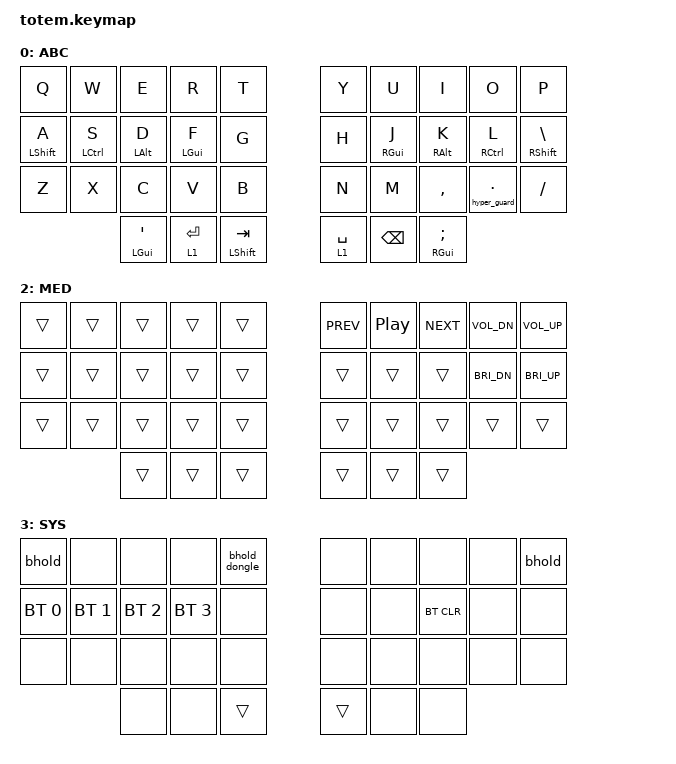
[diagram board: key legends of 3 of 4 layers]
#include <behaviors.dtsi>
#include <dt-bindings/zmk/keys.h>
#include <dt-bindings/zmk/bt.h>
#include <dt-bindings/zmk/outputs.h>

// Home row mods macro
#define HRML(k1,k2,k3,k4) &hml LSHFT k1 &hml LCTRL k2  &hml LALT k3  &hml LGUI k4
#define HRMR(k1,k2,k3,k4) &hmr RGUI k1  &hmr RALT k2  &hmr RCTRL k3  &hmr RSHFT k4

// Key positions for positional hold-tap, kept for reference. Currently unused:
// the homerow mods below deliberately do NOT use cross-hand gating (see the
// note on `hml`). This board is a TOTEMIST (36 keys), so these match the
// standard 36-key numbering -- see the matrix transform in
// config/boards/shields/totem/totem.dtsi:
//   Row 0:     0  1  2  3  4  |  5  6  7  8  9
//   Row 1:    10 11 12 13 14  | 15 16 17 18 19
//   Row 2:    20 21 22 23 24  | 25 26 27 28 29
//   Thumbs:      30 31 32     | 33 34 35
// The keymap mirrors the Toucan2's, minus its outer pinky columns and
// trackpad layer.
#define KEYS_L 0 1 2 3 4 10 11 12 13 14 20 21 22 23 24   // left-hand keys
#define KEYS_R 5 6 7 8 9 15 16 17 18 19 25 26 27 28 29   // right-hand keys
#define THUMBS 30 31 32 33 34 35                         // thumb keys

#define L0 0
#define L1 1
#define L2 2
#define L3 3

// Layer-tap, used by the left Enter/L1 and right Space/L1 thumbs.
//
// ZMK's stock `&lt` is `tap-preferred`, which only resolves a hold when the
// tapping term expires -- pressing and releasing another key while it is held
// does NOT trigger the hold. So a quick layer chord (hold the thumb, tap a
// key, release) completed inside 200ms emits SPACE plus that key instead of
// the layer keycode. `balanced` resolves the hold as soon as another key is
// pressed and released, which is exactly what a layer chord looks like.
&lt {
    flavor = "balanced";
    tapping-term-ms = <175>;
    quick-tap-ms = <125>;
};

/ {
    behaviors {
        // Thumb hold-tap: quote/Cmd on the left outer thumb and
        // semicolon/Cmd on the right outer thumb.
        //
        // Deliberately has NO `global-quick-tap` / `require-prior-idle-ms`.
        // Those make ZMK resolve the key to an *instant tap* whenever any other
        // key was pressed within the preceding window, no matter how long or
        // how hard the key is then held -- see is_quick_tap() in ZMK's
        // behavior_hold_tap.c. Since Shift is nearly always pressed immediately
        // after typing a letter, that reliably emitted TAB instead of SHIFT.
        //
        // Prior-idle gating is right for homerow mods (see hml/hmr below), but
        // wrong for thumbs, which are never pressed accidentally while typing.
        ht: hold_tap {
            label = "hold_tap";
            compatible = "zmk,behavior-hold-tap";
            #binding-cells = <2>;
            flavor = "balanced";
            tapping-term-ms = <175>;
            quick-tap-ms = <125>;
            bindings = <&kp>, <&kp>;
        };

        // Tab/Shift on the left inner thumb. `hold-preferred` makes Shift
        // win as soon as another key goes down, so a fast Shift+A roll that
        // lets go of the thumb before the letter still types `A`.
        shift_tab: shift_tab {
            compatible = "zmk,behavior-hold-tap";
            #binding-cells = <2>;
            flavor = "hold-preferred";
            tapping-term-ms = <175>;
            quick-tap-ms = <125>;
            bindings = <&kp>, <&kp>;
        };

        // These symbol combos keep their output unchanged while Shift is held.
        lpar_fixed: lpar_fixed {
            compatible = "zmk,behavior-mod-morph";
            #binding-cells = <0>;
            bindings = <&kp LPAR>, <&kp LPAR>;
            mods = <(MOD_LSFT|MOD_RSFT)>;
        };
        rpar_fixed: rpar_fixed {
            compatible = "zmk,behavior-mod-morph";
            #binding-cells = <0>;
            bindings = <&kp RPAR>, <&kp RPAR>;
            mods = <(MOD_LSFT|MOD_RSFT)>;
        };
        lbkt_fixed: lbkt_fixed {
            compatible = "zmk,behavior-mod-morph";
            #binding-cells = <0>;
            bindings = <&kp LBKT>, <&kp LBKT>;
            mods = <(MOD_LSFT|MOD_RSFT)>;
        };
        rbkt_fixed: rbkt_fixed {
            compatible = "zmk,behavior-mod-morph";
            #binding-cells = <0>;
            bindings = <&kp RBKT>, <&kp RBKT>;
            mods = <(MOD_LSFT|MOD_RSFT)>;
        };
        lbrc_fixed: lbrc_fixed {
            compatible = "zmk,behavior-mod-morph";
            #binding-cells = <0>;
            bindings = <&kp LBRC>, <&kp LBRC>;
            mods = <(MOD_LSFT|MOD_RSFT)>;
        };
        rbrc_fixed: rbrc_fixed {
            compatible = "zmk,behavior-mod-morph";
            #binding-cells = <0>;
            bindings = <&kp RBRC>, <&kp RBRC>;
            mods = <(MOD_LSFT|MOD_RSFT)>;
        };
        minus_fixed: minus_fixed {
            compatible = "zmk,behavior-mod-morph";
            #binding-cells = <0>;
            bindings = <&kp MINUS>, <&kp MINUS>;
            mods = <(MOD_LSFT|MOD_RSFT)>;
        };
        equal_fixed: equal_fixed {
            compatible = "zmk,behavior-mod-morph";
            #binding-cells = <0>;
            bindings = <&kp EQUAL>, <&kp EQUAL>;
            mods = <(MOD_LSFT|MOD_RSFT)>;
        };
        under_fixed: under_fixed {
            compatible = "zmk,behavior-mod-morph";
            #binding-cells = <0>;
            bindings = <&kp UNDER>, <&kp UNDER>;
            mods = <(MOD_LSFT|MOD_RSFT)>;
        };
        plus_fixed: plus_fixed {
            compatible = "zmk,behavior-mod-morph";
            #binding-cells = <0>;
            bindings = <&kp PLUS>, <&kp PLUS>;
            mods = <(MOD_LSFT|MOD_RSFT)>;
        };
        grave_fixed: grave_fixed {
            compatible = "zmk,behavior-mod-morph";
            #binding-cells = <0>;
            bindings = <&kp GRAVE>, <&kp GRAVE>;
            mods = <(MOD_LSFT|MOD_RSFT)>;
        };
        tilde_fixed: tilde_fixed {
            compatible = "zmk,behavior-mod-morph";
            #binding-cells = <0>;
            bindings = <&kp TILDE>, <&kp TILDE>;
            mods = <(MOD_LSFT|MOD_RSFT)>;
        };
        dqt_fixed: dqt_fixed {
            compatible = "zmk,behavior-mod-morph";
            #binding-cells = <0>;
            bindings = <&kp DQT>, <&kp DQT>;
            mods = <(MOD_LSFT|MOD_RSFT)>;
        };
        sqt_fixed: sqt_fixed {
            compatible = "zmk,behavior-mod-morph";
            #binding-cells = <0>;
            bindings = <&kp SQT>, <&kp SQT>;
            mods = <(MOD_LSFT|MOD_RSFT)>;
        };
        colon_fixed: colon_fixed {
            compatible = "zmk,behavior-mod-morph";
            #binding-cells = <0>;
            bindings = <&kp COLON>, <&kp COLON>;
            mods = <(MOD_LSFT|MOD_RSFT)>;
        };
        semi_fixed: semi_fixed {
            compatible = "zmk,behavior-mod-morph";
            #binding-cells = <0>;
            bindings = <&kp SEMI>, <&kp SEMI>;
            mods = <(MOD_LSFT|MOD_RSFT)>;
        };

        // Homerow mods.
        //
        // NOTE: no `hold-trigger-key-positions` / `hold-trigger-on-release`.
        // Those implement urob's cross-hand ("timeless") positional hold-tap,
        // where a homerow mod can ONLY resolve as a hold if the next key is on
        // the opposite half. That gate is absolute -- there is no timeout
        // escape hatch -- so holding LGUI (F) and pressing C, both left hand,
        // can never become a hold and just emits "fc". That breaks the whole
        // left-hand shortcut cluster (CMD/CTRL + Q W A S Z X C V) and every
        // left-hand capital via LSHFT on A.
        //
        // With the positional gate removed, `require-prior-idle-ms` is the
        // main guard against false mods mid-word, and the tapping term becomes
        // the window in which a same-hand roll could still resolve as a hold
        // (balanced resolves on the other key's release). 190ms with a 100ms
        // prior-idle (was 220/150) biases toward HOLD, since missed holds
        // proved far more common than false ones.
        //
        // Trade-off: a fast same-hand roll that *starts* on the homerow after
        // >100ms idle ("as", "sad", "fad") can register a mod. If that becomes
        // the more annoying failure mode, re-add the two properties below
        // (KEYS_R THUMBS for hml, KEYS_L THUMBS for hmr) and use combos for
        // same-hand shortcuts, which is how urob handles it.
        hml: home_row_mod_left {
            label = "hrm_left";
            compatible = "zmk,behavior-hold-tap";
            #binding-cells = <2>;
            flavor = "balanced";
            tapping-term-ms = <190>;
            quick-tap-ms = <120>;
            require-prior-idle-ms = <100>;
            bindings = <&kp>, <&kp>;
        };

        hmd: home_row_mod_d {
            label = "hrm_d";
            compatible = "zmk,behavior-hold-tap";
            #binding-cells = <2>;
            flavor = "balanced";
            tapping-term-ms = <160>;
            quick-tap-ms = <120>;
            require-prior-idle-ms = <50>;
            bindings = <&kp>, <&kp>;
        };

        hmr: home_row_mod_right {
            label = "hrm_right";
            compatible = "zmk,behavior-hold-tap";
            #binding-cells = <2>;
            flavor = "balanced";
            tapping-term-ms = <190>;
            quick-tap-ms = <120>;
            require-prior-idle-ms = <100>;
            bindings = <&kp>, <&kp>;
        };

        // Software bootloader entry for the maintenance layer. This uses a
        // dedicated long-press behavior instead of `zmk,behavior-hold-tap`.
        // Both inner thumbs are hold-tap keys, and ZMK v0.3 rejects a second
        // hold-tap while either thumb remains held. Tap does nothing; a 2s+
        // hold invokes `&bootloader` with the original key's split source.
        //
        // This exists because ZMK behaviors with BEHAVIOR_LOCALITY_EVENT_SOURCE
        // (which &bootloader uses) execute on whichever half the triggering
        // key physically lives on, even though all keymap/behavior logic runs
        // on the central (left) half -- so P, physically on the
        // right board, reliably bootloaders the right half over BLE even
        // when its physical reset button doesn't.
        bhold: bootloader_hold {
            label = "bootloader_hold";
            compatible = "zmk,behavior-long-press";
            #binding-cells = <0>;
            duration-ms = <2000>;
            bindings = <&bootloader>;
        };

        // Same 2s hold, retargeted at the split central via `central`. In
        // dongle mode that is the keyless dongle, which otherwise has no way
        // into its UF2 bootloader short of opening its case to reach the reset
        // button. Standalone, the central is the left half, so this simply
        // duplicates the left pinky hold.
        bhold_dongle: bootloader_hold_dongle {
            compatible = "zmk,behavior-long-press";
            #binding-cells = <0>;
            duration-ms = <2000>;
            bindings = <&bootloader>;
            central;
        };
        // `&kp` that drops the key while Ctrl, Shift, Alt and GUI are all
        // held. Resting on the four left homerow mods resolves them all as
        // holds, and with `.` that is macOS's sysdiagnose chord, which kept
        // firing by accident. Any other modifier combination is unaffected.
        hyper_guard: hyper_guard {
            compatible = "zmk,behavior-hyper-guard";
            #binding-cells = <1>;
        };
    };

    combos {
        compatible = "zmk,combos";
        // Letter combos need both keys within 21ms (ZMK's default is 50ms), so
        // quick rolls while typing, like O then P, stay as plain letters.
        combo_esc_op {
            timeout-ms = <21>;
            key-positions = <8 9>;  // Combo o+p for ESCAPE
            bindings = <&kp ESC>;
        };
        combo_esc_qw {
            timeout-ms = <21>;
            key-positions = <0 1>;  // Combo q+w for ESCAPE
            bindings = <&kp ESC>;
        };
        // Symbol combos work on every layer and ignore held Shift.
        combo_left_paren {
            timeout-ms = <21>;
            key-positions = <22 23>;  // C+V
            bindings = <&lpar_fixed>;
        };
        combo_right_paren {
            timeout-ms = <21>;
            key-positions = <26 27>;  // M+COMMA
            bindings = <&rpar_fixed>;
        };
        combo_left_bracket {
            timeout-ms = <21>;
            key-positions = <12 13>;  // D+F
            bindings = <&lbkt_fixed>;
        };
        combo_right_bracket {
            timeout-ms = <21>;
            key-positions = <16 17>;  // J+K
            bindings = <&rbkt_fixed>;
        };
        combo_left_brace {
            timeout-ms = <21>;
            key-positions = <2 3>;  // E+R
            bindings = <&lbrc_fixed>;
        };
        combo_right_brace {
            timeout-ms = <21>;
            key-positions = <6 7>;  // U+I
            bindings = <&rbrc_fixed>;
        };
        combo_minus {
            timeout-ms = <21>;
            key-positions = <21 22>;  // X+C
            bindings = <&minus_fixed>;
        };
        combo_equal {
            timeout-ms = <21>;
            key-positions = <27 28>;  // COMMA+.
            bindings = <&equal_fixed>;
        };
        combo_underscore {
            timeout-ms = <21>;
            key-positions = <1 2>;  // W+E
            bindings = <&under_fixed>;
        };
        combo_plus {
            timeout-ms = <21>;
            key-positions = <7 8>;  // I+O
            bindings = <&plus_fixed>;
        };
        combo_grave {
            timeout-ms = <21>;
            key-positions = <10 11>;  // A+S
            bindings = <&grave_fixed>;
        };
        combo_tilde {
            timeout-ms = <21>;
            key-positions = <18 19>;  // L+backslash
            bindings = <&tilde_fixed>;
        };
        combo_double_quote {
            timeout-ms = <21>;
            key-positions = <20 21>;  // Z+X
            bindings = <&dqt_fixed>;
        };
        combo_single_quote {
            timeout-ms = <21>;
            key-positions = <28 29>;  // ./
            bindings = <&sqt_fixed>;
        };
        combo_colon {
            timeout-ms = <21>;
            key-positions = <11 12>;  // S+D
            bindings = <&colon_fixed>;
        };
        combo_semicolon {
            timeout-ms = <21>;
            key-positions = <17 18>;  // K+L
            bindings = <&semi_fixed>;
        };
        // Tap Enter/L1 and Backspace together once for Caps Word.
        combo_caps_word {
            timeout-ms = <21>;
            key-positions = <31 34>;
            bindings = <&caps_word>;
        };
        combo_maintenance_layer {
            timeout-ms = <100>;
            key-positions = <30 35>;  // Hold both far outer thumbs.
            bindings = <&mo L3>;
            layers = <L0 L1 L2>;
        };
    };


    keymap {
        compatible = "zmk,keymap";

        layer_zero {
            display-name = "ABC";
            bindings = <
        //     ╭───────────┬───────────┬───────────┬───────────┬───────────╮   ╭───────────┬───────────┬───────────┬───────────┬───────────╮
                &kp Q       &kp W       &kp E       &kp R       &kp T           &kp Y       &kp U       &kp I       &kp O       &kp P
        //     ├───────────├───────────├───────────├───────────├───────────┤   ├───────────├───────────├───────────├───────────├───────────┤
                &hml LSHFT A &hml LCTRL S &hmd LALT D &hml LGUI F &kp G     &kp H       &hmr RGUI J &hmr RALT K &hmr RCTRL L &hmr RSHFT BSLH
        //     ├───────────├───────────├───────────├───────────├───────────┤   ├───────────├───────────├───────────├───────────├───────────┤
                &kp Z       &kp X       &kp C       &kp V       &kp B           &kp N       &kp M       &kp COMMA   &hyper_guard DOT &kp FSLH
        //     ╰───────────┴───────────┴───────────├───────────├───────────┼───────────┤   ├───────────├───────────┼───────────┴───────────┴───────────╯
                                                &ht LGUI SQT   &lt L1 RET &shift_tab LSHFT TAB &lt L1 SPACE  &kp BSPC   &ht RGUI SEMI
        //                                         ╰───────────┴───────────┴───────────╯   ╰───────────┴───────────┴───────────╯
            >;
        };


        layer_one {
            display-name = "NUM";
            bindings = <
        //     ╭───────────┬───────────┬───────────┬───────────┬───────────╮   ╭───────────┬───────────┬───────────┬───────────┬───────────╮
                &kp ESC     &kp N1      &kp N2      &kp N3      &trans          &trans      &trans      &kp UP      &kp MINUS   &kp EQUAL
        //     ├───────────├───────────├───────────├───────────├───────────┤   ├───────────├───────────├───────────├───────────├───────────┤
                HRML(GRAVE,     N4,         N5,         N6)     &trans          &trans      &kp LEFT    &kp DOWN    &kp RIGHT   &trans
        //     ├───────────├───────────├───────────├───────────├───────────┤   ├───────────├───────────├───────────├───────────├───────────┤
                &trans      &kp N7      &kp N8      &kp N9      &kp N0          &kp SEMI    &kp SQT     &kp LBKT    &kp RBKT    &trans
        //     ╰───────────┴───────────┴───────────├───────────├───────────┼───────────┤   ├───────────├───────────┼───────────┴───────────┴───────────╯
                                                &ht LGUI GRAVE &trans     &trans          &trans      &trans      &trans
        //                                         ╰───────────┴───────────┴───────────╯   ╰───────────┴───────────┴───────────╯
            >;
        };



        layer_two {
            display-name = "MED";
            bindings = <
        //     ╭───────────┬───────────┬───────────┬───────────┬───────────╮   ╭───────────┬───────────┬───────────┬───────────┬───────────╮
                &trans      &trans      &trans      &trans      &trans          &kp C_PREV  &kp C_PP    &kp C_NEXT  &kp C_VOL_DN   &kp C_VOL_UP
        //     ├───────────├───────────├───────────├───────────├───────────┤   ├───────────├───────────├───────────├───────────├───────────┤
                &trans      &trans      &trans      &trans      &trans          &trans      &trans      &trans      &kp C_BRI_DN   &kp C_BRI_UP
        //     ├───────────├───────────├───────────├───────────├───────────┤   ├───────────├───────────├───────────├───────────├───────────┤
                &trans      &trans      &trans      &trans      &trans          &trans      &trans      &trans      &trans      &trans
        //     ╰───────────┴───────────┴───────────├───────────├───────────┼───────────┤   ├───────────├───────────┼───────────┴───────────┴───────────╯
                                                   &trans      &trans      &trans          &trans      &trans      &trans
        //                                         ╰───────────┴───────────┴───────────╯   ╰───────────┴───────────┴───────────╯
            >;
        };

        // Dedicated maintenance layer. Hold both far outer thumbs (positions
        // 30 and 35) to activate it. This leaves the center Shift + L1 thumb
        // chord completely untouched. The bootloader holds sit on Q/P; hold
        // the corresponding side for two seconds to enter that half's UF2
        // bootloader. Bluetooth clear is on K.
        //
        // `T` is a third 2s bootloader hold, for the USB dongle in dongle mode
        // (the left half when standalone). It sits on the inner column, between
        // the two halves' pinky holds, like the dongle sits between the halves.
        layer_three {
            display-name = "SYS";
            bindings = <
                &bhold &none &none &none &bhold_dongle   &none &none &none &none &bhold
                &bt BT_SEL 0 &bt BT_SEL 1 &bt BT_SEL 2 &bt BT_SEL 3 &none   &none &none &bt BT_CLR &none &none
                &none &none &none &none &none   &none &none &none &none &none
                      &none &none &trans              &trans &none &none
            >;
        };
    };
};
